# PIC32CX2051MTSH128 register map
Vendor: Microchip Technology; Series: PIC32CXMTSH; File version: 0
CPU: CM4 r0p1, little endian, MPU, FPU, 4 interrupt priority bits, 96 interrupts
Registers are 32-bit, read-write, reset 0x0 unless marked. A register's access mark holds for its fields unless they carry their own. Offsets are from the block's base; [hi:lo] are bit positions; {n}, {i} and the like mark numbered series.

## LOCKBIT
Base 0x00000000
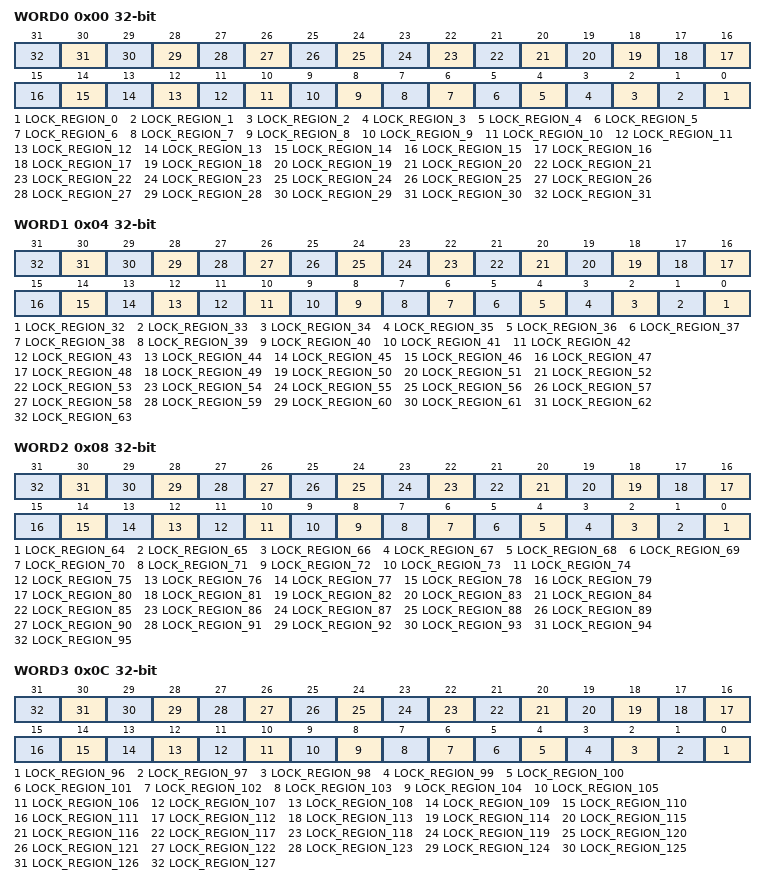
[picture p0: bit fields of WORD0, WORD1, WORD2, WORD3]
0x00 WORD0 — Lock Bits Word 0
  [n] LOCK_REGION_{n} (n=0..31)
0x04 WORD1 — Lock Bits Word 1
  [n-32] LOCK_REGION_{n} (n=32..63)
0x08 WORD2 — Lock Bits Word 2
  [n-64] LOCK_REGION_{n} (n=64..95)
0x0C WORD3 — Lock Bits Word 3
  [n-96] LOCK_REGION_{n} (n=96..127)
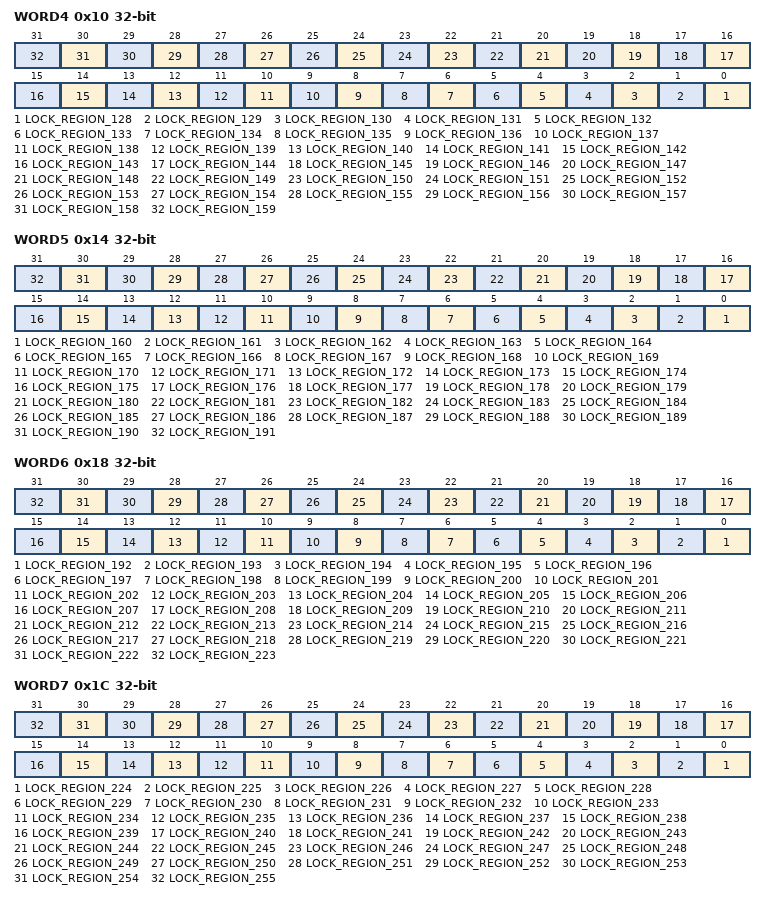
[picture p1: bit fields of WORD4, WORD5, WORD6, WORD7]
0x10 WORD4 — Lock Bits Word 4
  [n-128] LOCK_REGION_{n} (n=128..159)
0x14 WORD5 — Lock Bits Word 5
  [n-160] LOCK_REGION_{n} (n=160..191)
0x18 WORD6 — Lock Bits Word 6
  [n-192] LOCK_REGION_{n} (n=192..223)
0x1C WORD7 — Lock Bits Word 7
  [n-224] LOCK_REGION_{n} (n=224..255)
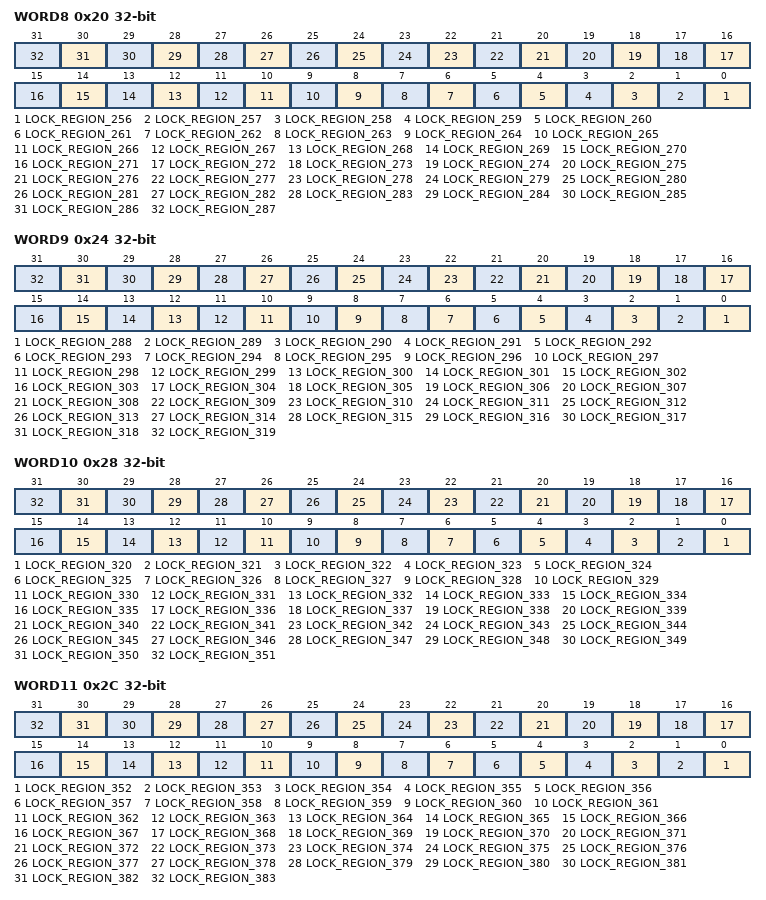
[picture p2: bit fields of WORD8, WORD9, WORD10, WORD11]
0x20 WORD8 — Lock Bits Word 8
  [n-256] LOCK_REGION_{n} (n=256..287)
0x24 WORD9 — Lock Bits Word 9
  [n-288] LOCK_REGION_{n} (n=288..319)
0x28 WORD10 — Lock Bits Word 10
  [n-320] LOCK_REGION_{n} (n=320..351)
0x2C WORD11 — Lock Bits Word 11
  [n-352] LOCK_REGION_{n} (n=352..383)
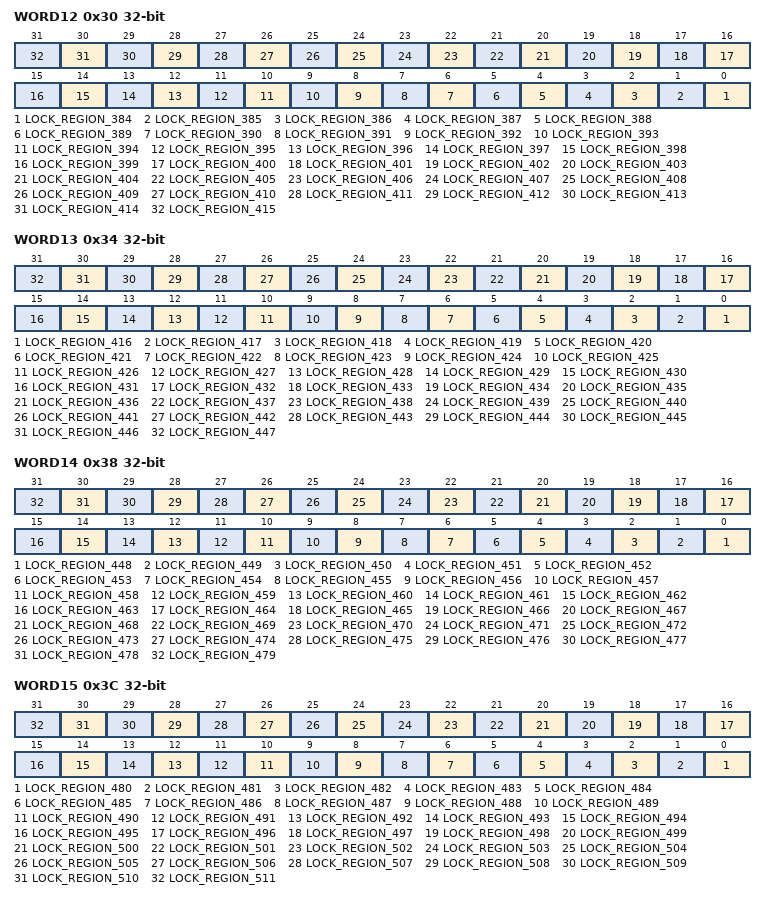
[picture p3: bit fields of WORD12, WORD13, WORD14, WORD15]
0x30 WORD12 — Lock Bits Word 12
  [n-384] LOCK_REGION_{n} (n=384..415)
0x34 WORD13 — Lock Bits Word 13
  [n-416] LOCK_REGION_{n} (n=416..447)
0x38 WORD14 — Lock Bits Word 14
  [n-448] LOCK_REGION_{n} (n=448..479)
0x3C WORD15 — Lock Bits Word 15
  [n-480] LOCK_REGION_{n} (n=480..511)

## CoreDebug
Base 0xE000EDF0
0x00 DHCSR — Debug Halting Control and Status Register
  [25] S_RESET_ST ro — Reset Status
  [24] S_RETIRE_ST ro — Retire Status
  [19] S_LOCKUP ro — Locked up status
  [18] S_SLEEP ro — Sleep status
  [17] S_HALT ro — Debug state status
  [16] S_REGRDY ro — Transfer complete flag
  [31:16] DBGKEY wo — Debug key
  [5] C_SNAPSTALL — Allow imprecise entry to Debug state
  [3] C_MASKINTS — Mask PendSV, SysTick and external configurable interrupts
  [2] C_STEP — Processor step bit
  [1] C_HALT — Processor halt bit
  [0] C_DEBUGEN — Halting debug enable bit
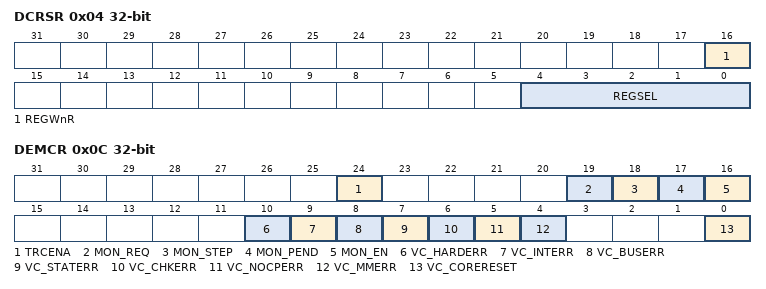
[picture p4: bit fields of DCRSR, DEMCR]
0x04 DCRSR wo — Debug Core Register Selector Register
  [16] REGWnR — Specifies the access type for the transfer
  [4:0] REGSEL — Specifies the Arm core register, special-purpose register, or Floating-point Extension register, to transfer
0x08 DCRDR — Debug Core Register Data Register
  [16] DBGTMP — Data temporary cache
0x0C DEMCR — Debug Exception and Monitor Control Register
  [24] TRCENA, [19] MON_REQ, [18] MON_STEP, [17] MON_PEND, [16] MON_EN, [10] VC_HARDERR, [9] VC_INTERR, [8] VC_BUSERR, [7] VC_STATERR, [6] VC_CHKERR, [5] VC_NOCPERR, [4] VC_MMERR, [0] VC_CORERESET

## ETM — Embedded Trace Macrocell
Base 0xE0041000
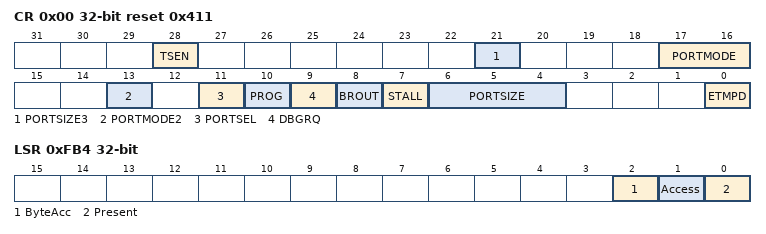
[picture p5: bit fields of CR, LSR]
0x00 CR reset 0x411 — ETM Main Control Register
  [28] TSEN — TimeStamp Enable
  [21] PORTSIZE3 — Port Size bit 3
  [17:16] PORTMODE — Port Mode bits 1:0
  [13] PORTMODE2 — Port Mode bit 2
  [11] PORTSEL — ETM Port Select
  [10] PROG — ETM Programming
  [9] DBGRQ — Debug Request Control
  [8] BROUT — Branch Output
  [7] STALL — Stall Processor
  [6:4] PORTSIZE — Port Size bits 2:0
  [0] ETMPD — ETM Power Down
0x04 CCR ro reset 0x8C802000 — ETM Configuration Code Register
0x08 TRIGGER — ETM Trigger Event Register
0x10 SR — ETM Status Register
0x14 SCR ro reset 0x20D09 — ETM System Configuration Register
0x20 TEEVR — ETM TraceEnable Event Register
0x24 TECR1 — ETM TraceEnable Control 1 Register
0x28 FFLR — ETM FIFO Full Level Register
0x140 CNTRLDVR1 — ETM Free-running Counter Reload Value
0x1E0 SYNCFR ro reset 0x400 — ETM Synchronization Frequency Register
0x1E4 IDR ro reset 0x4114F250 — ETM ID Register
0x1E8 CCER ro reset 0x18541800 — ETM Configuration Code Extension Register
0x1F0 TESSEICR — ETM TraceEnable Start/Stop EmbeddedICE Control Register
0x1F8 TSEVT — ETM TimeStamp Event Register
0x200 TRACEIDR — ETM CoreSight Trace ID Register
0x208 IDR2 ro — ETM ID Register 2
0x314 PDSR ro reset 0x1 — ETM Device Power-Down Status Register
0xEE0 ITMISCIN ro — ETM Integration Test Miscellaneous Inputs
0xEE8 ITTRIGOUT wo — ETM Integration Test Trigger Out
0xEF0 ITATBCTR2 ro — ETM Integration Test ATB Control 2
0xEF8 ITATBCTR0 wo — ETM Integration Test ATB Control 0
0xF00 ITCTRL — ETM Integration Mode Control Register
  [0] INTEGRATION
0xFA0 CLAIMSET — ETM Claim Tag Set Register
0xFA4 CLAIMCLR — ETM Claim Tag Clear Register
0xFB0 LAR wo — ETM Lock Access Register
0xFB4 LSR ro — ETM Lock Status Register
  [2] ByteAcc, [1] Access, [0] Present
0xFB8 AUTHSTATUS ro — ETM Authentication Status Register
0xFCC DEVTYPE ro reset 0x13 — ETM CoreSight Device Type Register
0xFD0 PIDR4 ro reset 0x4 — ETM Peripheral Identification Register #4
{0xFC0+4i} PIDR{i} ro (i=5..7) — ETM Peripheral Identification Register #{i}
0xFE0 PIDR0 ro reset 0x25 — ETM Peripheral Identification Register #0
0xFE4 PIDR1 ro reset 0xB9 — ETM Peripheral Identification Register #1
0xFE8 PIDR2 ro reset 0xB — ETM Peripheral Identification Register #2
0xFEC PIDR3 ro — ETM Peripheral Identification Register #3
0xFF0 CIDR0 ro reset 0xD — ETM Component Identification Register #0
0xFF4 CIDR1 ro reset 0x90 — ETM Component Identification Register #1
0xFF8 CIDR2 ro reset 0x5 — ETM Component Identification Register #2
0xFFC CIDR3 ro reset 0xB1 — ETM Component Identification Register #3
